# A31S13x register map
Vendor: VENDOR ABOV Semiconductor Co., Ltd.; Series: A31S13x; File version: 1.0
CPU: CM0+ r0p1, little endian, no MPU, no FPU, VTOR, 2 interrupt priority bits
Registers are 32-bit, read-write, reset 0x0 unless marked. A register's access mark holds for its fields unless they carry their own. Offsets are from the block's base; [hi:lo] are bit positions; {n}, {i} and the like mark numbered series.

## CRC — Cyclic Redundancy Check and Checksum
Base 0x30001000
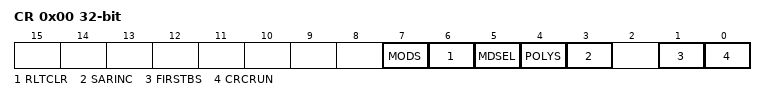
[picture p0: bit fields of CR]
0x00 CR — CRC/Checksum Control Register
  [7] MODS — User/Auto Mode Selection
    0=User Mode (Calculate every data written to the CRC_IN register); 1=Auto Mode (Calculate till CRC_SADR == CRC_EADR)
  [6] RLTCLR — CRC/Checksum Result Data Register (CRCRLT) Initialization
    0=NoEffect; 1=Initialize the CRC_RLT register with the value of CRC_INIT. (This bit is automatically cleared to '0' after operation.)
  [5] MDSEL — CRC/Checksum Selection
    0=CRC (Select CRC.); 1=Checksum (Select Checksum.)
  [4] POLYS — Polynomial Selection (CRC only)
    0=CRC16_CCITT (CRC16-CCITT (G1(x) = x16 + x12 + x5 + 1)); 1=CRC16 (CRC16 (G2(x) = x16 + x15 + x2 + 1))
  [3] SARINC — CRC/Checksum Start Address Auto Increment Control (User mode only)
    0=Disable (No effect.); 1=Enable (The CRC/Checksum start address register is incremented as the selected input size every writing to the CRC_IN register.)
  [1] FIRSTBS — First Shifted-in Selection (CRC only)
    0=msbFirst; 1=lsbFirst
  [0] CRCRUN — CRC/Checksum Start Control and Busy
    0=Stop (Not busy. The CRC operation can be finished by writing '0' to this bit while running.); 1=Start CRC operation. This bit is automatically cleared to '0' when the value of CRC_SADR register reaches the value of CRC_EADR register.
0x04 IN — CRC/Checksum Input Data Register
  [31:0] INDATA — CRC Input Data
0x08 RLT ro reset 0xFFFF — CRC/Checksum Result Data Register
  [15:0] RLTDATA — CRC Result Data
0x0C INIT — CRC/Checksum Initial Data Register
  [15:0] INIDATA — CRC Initial Data
0x10 SADR reset 0x10000000 — CRC/Checksum Start Address Register
  [31:2] SADR — CRC Start Address
0x14 EADR reset 0x1001FFFC — CRC/Checksum End Address Register
  [31:2] EADR — CRC End Address

## DMACn — DMA Controller Channel n
Base 0x5D000000
Same registers: DMAC0 0x40005D00, DMAC1 0x40005D20
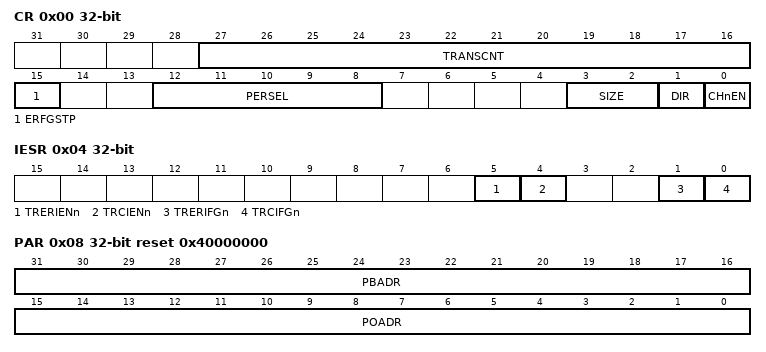
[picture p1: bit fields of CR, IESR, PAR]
0x00 CR — DMA Channel n Control Register
  [27:16] TRANSCNT — The number of times to transfer
  [15] ERFGSTP — Error Flag Stop
    0=Disable DMA stop function by an error of peripheral; 1=Enable DMA stop function by an error of peripheral
  [12:8] PERSEL — Peripheral Selection
    0=Idle (Channel idle); 1=SPI0Rx; 2=SPI0Tx; 3=SPI1Rx; 4=SPI1Tx; 5=USART10Rx; 6=USART10Tx; 7=I2C0Rx; 8=I2C0Tx; 9=I2C1Rx; 10=I2C1Tx; 11=UART0Rx; 12=UART0Tx; 13=UART1Rx; 14=UART1Tx; 15=USART11Rx; 16=USART11Tx; 17=I2C2Rx; 18=I2C2Tx; 19=USART12Rx; 20=USART12Tx
  [3:2] SIZE — Transfer Size Selection
    0=8 bits; 1=16 bits; 2=32 bits
  [1] DIR — Transfer Direction
    0=MemToPeri (Transfer is from memory to peripheral.); 1=PeriToMem (Transfer is from peripheral to memory.)
  [0] CHnEN — DMA Channel Enable
    0=Disable channel n; 1=Enable channel n
0x04 IESR — DMA Channel n Interrupt Enable and Status Register
  [5] TRERIENn — Transfer Error Interrupt Enable
    0=Disable transfer error interrupt; 1=Enable transfer error interrupt
  [4] TRCIENn — Transfer Complete Interrupt Enable
    0=Disable transfer complete interrupt; 1=Enable transfer complete interrupt
  [1] TRERIFGn — Transfer Error Interrupt Flag
    0=No request occurred; 1=Request occurred
  [0] TRCIFGn — Transfer Complete Interrupt Flag
    0=No request occurred; 1=Request occurred
0x08 PAR reset 0x40000000 — DMA Channel n Peripheral Address Register
  [31:16] PBADR — Peripheral Base Address
  [15:0] POADR — Peripheral Offset Address
0x0C MAR reset 0x20000000 — DMA Channel n Memory Address Register
  [31:0] MAR — Memory Address

## ADC — 12 Bit A/D Converter
Base 0x40003000
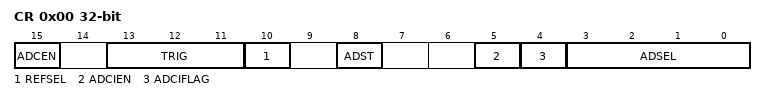
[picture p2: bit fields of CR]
0x00 CR — A/D Converter Control Register
  [15] ADCEN — ADC Module Enable
    0=Disable ADC module operation; 1=Enable ADC module operation
  [13:11] TRIG — ADC Trigger Signal Selection
    0=ADST (Select ADST.); 1=TIMER10 (Select TIMER10 A-Match Signal.); 2=TIMER11 (Select TIMER11 A-Match Signal.); 3=TIMER12 (Select TIMER12 A-Match Signal.)
  [10] REFSEL — ADC Reference Selection
    0=Vdd (Select analog power (VDD).); 1=AVref (Select external reference (AVREF).)
  [8] ADST — ADC Conversion Start
    0=NoEffect; 1=Start (Trigger signal generation for conversion start.)
  [5] ADCIEN — ADC Interrupt Enable
    0=Disable ADC interrupt; 1=Enable ADC interrupt
  [4] ADCIFLAG — ADC Interrupt Flag
    0=No request occurred; 1=Request occurred
  [3:0] ADSEL — A/D Converter Channel Selection
    {v}=AN{v} (Select AN{v}.) (v=0..10); 11=AN11 (Select AN11); 12=AN12 (Select AN12); 13=AN13 (Select AN13)
0x04 DR ro (reset mask 0xFFFFF000) — A/D Converter Data Register
  [11:0] ADDATA — A/D Converter Result Data
0x08 PREDR reset 0xF — A/D Converter Prescaler Data Register
  [4:0] PRED — A/D Converter Prescaler Data
